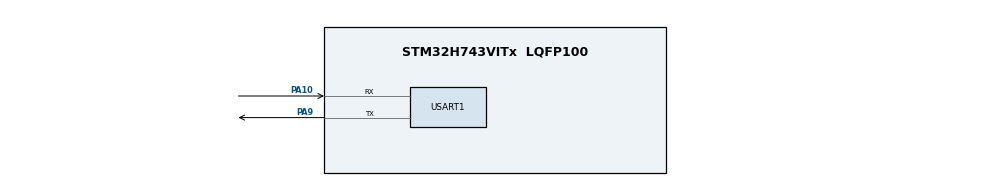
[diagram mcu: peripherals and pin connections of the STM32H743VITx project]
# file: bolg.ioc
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CORTEX_M7.CPU_DCache=Enabled
CORTEX_M7.CPU_ICache=Enabled
Dma.Request0=USART1_RX
Dma.Request1=USART1_TX
Dma.USART1_RX.0.Direction=DMA_PERIPH_TO_MEMORY
Dma.USART1_RX.0.EventEnable=DISABLE
Dma.USART1_RX.0.FIFOMode=DMA_FIFOMODE_DISABLE
Dma.USART1_RX.0.Instance=DMA1_Stream0
Dma.USART1_RX.0.MemDataAlignment=DMA_MDATAALIGN_BYTE
Dma.USART1_RX.0.MemInc=DMA_MINC_ENABLE
Dma.USART1_RX.0.Mode=DMA_NORMAL
Dma.USART1_RX.0.PeriphDataAlignment=DMA_PDATAALIGN_BYTE
Dma.USART1_RX.0.PeriphInc=DMA_PINC_DISABLE
Dma.USART1_RX.0.Polarity=HAL_DMAMUX_REQ_GEN_RISING
Dma.USART1_RX.0.Priority=DMA_PRIORITY_VERY_HIGH
Dma.USART1_RX.0.RequestNumber=1
Dma.USART1_RX.0.SignalID=NONE
Dma.USART1_RX.0.SyncEnable=DISABLE
Dma.USART1_RX.0.SyncPolarity=HAL_DMAMUX_SYNC_NO_EVENT
Dma.USART1_RX.0.SyncRequestNumber=1
Dma.USART1_RX.0.SyncSignalID=NONE
Dma.USART1_TX.1.Direction=DMA_MEMORY_TO_PERIPH
Dma.USART1_TX.1.EventEnable=DISABLE
Dma.USART1_TX.1.FIFOMode=DMA_FIFOMODE_DISABLE
Dma.USART1_TX.1.Instance=DMA1_Stream1
Dma.USART1_TX.1.MemDataAlignment=DMA_MDATAALIGN_BYTE
Dma.USART1_TX.1.MemInc=DMA_MINC_ENABLE
Dma.USART1_TX.1.Mode=DMA_NORMAL
Dma.USART1_TX.1.PeriphDataAlignment=DMA_PDATAALIGN_BYTE
Dma.USART1_TX.1.PeriphInc=DMA_PINC_DISABLE
Dma.USART1_TX.1.Polarity=HAL_DMAMUX_REQ_GEN_RISING
Dma.USART1_TX.1.Priority=DMA_PRIORITY_VERY_HIGH
Dma.USART1_TX.1.RequestNumber=1
Dma.USART1_TX.1.SignalID=NONE
Dma.USART1_TX.1.SyncEnable=DISABLE
Dma.USART1_TX.1.SyncPolarity=HAL_DMAMUX_SYNC_NO_EVENT
Dma.USART1_TX.1.SyncRequestNumber=1
Dma.USART1_TX.1.SyncSignalID=NONE
Mcu.Family=STM32H7
Mcu.Name=STM32H743VITx
Mcu.Package=LQFP100
NVIC.DMA1_Stream0_IRQn=true\:0\:0\:false\:false\:true\:false\:true
NVIC.DMA1_Stream1_IRQn=true\:0\:0\:false\:false\:true\:false\:true
NVIC.PriorityGroup=NVIC_PRIORITYGROUP_4
NVIC.USART1_IRQn=true\:3\:0\:true\:false\:true\:true\:true
PA10.Mode=Asynchronous
PA10.Signal=USART1_RX
PA13\ (JTMS/SWDIO).Mode=Serial_Wire
PA13\ (JTMS/SWDIO).Signal=DEBUG_JTMS-SWDIO
PA14\ (JTCK/SWCLK).Mode=Serial_Wire
PA14\ (JTCK/SWCLK).Signal=DEBUG_JTCK-SWCLK
PA9.Mode=Asynchronous
PA9.Signal=USART1_TX
PC14-OSC32_IN\ (OSC32_IN).Mode=LSE-External-Oscillator
PC14-OSC32_IN\ (OSC32_IN).Signal=RCC_OSC32_IN
PC15-OSC32_OUT\ (OSC32_OUT).Mode=LSE-External-Oscillator
PC15-OSC32_OUT\ (OSC32_OUT).Signal=RCC_OSC32_OUT
PH0-OSC_IN\ (PH0).Mode=HSE-External-Oscillator
PH0-OSC_IN\ (PH0).Signal=RCC_OSC_IN
PH1-OSC_OUT\ (PH1).Mode=HSE-External-Oscillator
PH1-OSC_OUT\ (PH1).Signal=RCC_OSC_OUT
ProjectManager.HeapSize=0x200
ProjectManager.StackSize=0x400
ProjectManager.TargetToolchain=MDK-ARM V5.27
RCC.ADCFreq_Value=50390625
RCC.APB1Freq_Value=120000000
RCC.APB2Freq_Value=120000000
RCC.APB3Freq_Value=120000000
RCC.APB4Freq_Value=120000000
RCC.CortexFreq_Value=480000000
RCC.D1PPRE=RCC_APB3_DIV2
RCC.D2PPRE1=RCC_APB1_DIV2
RCC.D2PPRE2=RCC_APB2_DIV2
RCC.D3PPRE=RCC_APB4_DIV2
RCC.DIVM1=5
RCC.DIVN1=192
RCC.HCLKFreq_Value=240000000
RCC.HPRE=RCC_HCLK_DIV2
RCC.PLL2FRACN=0
RCC.PLL3FRACN=0
RCC.PLLFRACN=0
RCC.PLLSourceVirtual=RCC_PLLSOURCE_HSE
RCC.SYSCLKFreq_VALUE=480000000
RCC.SYSCLKSource=RCC_SYSCLKSOURCE_PLLCLK
RCC.USBFreq_Value=480000000
USART1.VirtualMode-Asynchronous=VM_ASYNC
board=custom

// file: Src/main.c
/* USER CODE BEGIN Header */
/**
  ******************************************************************************
  * @file           : main.c
  * @brief          : Main program body
  ******************************************************************************
  * @attention
  *
  * <h2><center>&copy; Copyright (c) 2020 STMicroelectronics.
  * All rights reserved.</center></h2>
  *
  * This software component is licensed by ST under BSD 3-Clause license,
  * the "License"; You may not use this file except in compliance with the
  * License. You may obtain a copy of the License at:
  *                        opensource.org/licenses/BSD-3-Clause
  *
  ******************************************************************************
  */
/* USER CODE END Header */

#include "main.h"
#include "dma.h"
#include "usart.h"
#include "gpio.h"

/* USER CODE BEGIN Includes */
#include "My_Uart.h"
/* USER CODE END Includes */

void SystemClock_Config(void);

int main(void)
{

  /* Enable I-Cache---------------------------------------------------------*/
  SCB_EnableICache();

  /* Enable D-Cache---------------------------------------------------------*/
  SCB_EnableDCache();

  /* MCU Configuration--------------------------------------------------------*/

  /* Reset of all peripherals, Initializes the Flash interface and the Systick. */
  HAL_Init();

  /* Configure the system clock */
  SystemClock_Config();

  /* Initialize all configured peripherals */
  MX_GPIO_Init();
  MX_DMA_Init();
  MX_USART1_UART_Init();
  /* USER CODE BEGIN 2 */
__HAL_UART_ENABLE_IT(&huart1, UART_IT_IDLE);
  /* USER CODE END 2 */

  /* Infinite loop */
  /* USER CODE BEGIN WHILE */
  while (1)
  {
	if(UsartType.RX_flag)
	{
		UsartType.RX_flag=0;
		HAL_UART_Transmit_DMA(&huart1, (uint8_t *)UsartType.RX_pData, RX_LEN);
	}
    /* USER CODE END WHILE */

  }
}

void SystemClock_Config(void)
{
  RCC_OscInitTypeDef RCC_OscInitStruct = {0};
  RCC_ClkInitTypeDef RCC_ClkInitStruct = {0};
  RCC_PeriphCLKInitTypeDef PeriphClkInitStruct = {0};

  /** Supply configuration update enable
  */
  HAL_PWREx_ConfigSupply(PWR_LDO_SUPPLY);
  /** Configure the main internal regulator output voltage
  */
  __HAL_PWR_VOLTAGESCALING_CONFIG(PWR_REGULATOR_VOLTAGE_SCALE0);

  while(!__HAL_PWR_GET_FLAG(PWR_FLAG_VOSRDY)) {}
  /** Initializes the CPU, AHB and APB busses clocks
  */
  RCC_OscInitStruct.OscillatorType = RCC_OSCILLATORTYPE_HSE;
  RCC_OscInitStruct.HSEState = RCC_HSE_ON;
  RCC_OscInitStruct.PLL.PLLState = RCC_PLL_ON;
  RCC_OscInitStruct.PLL.PLLSource = RCC_PLLSOURCE_HSE;
  RCC_OscInitStruct.PLL.PLLM = 5;
  RCC_OscInitStruct.PLL.PLLN = 192;
  RCC_OscInitStruct.PLL.PLLP = 2;
  RCC_OscInitStruct.PLL.PLLQ = 2;
  RCC_OscInitStruct.PLL.PLLR = 2;
  RCC_OscInitStruct.PLL.PLLRGE = RCC_PLL1VCIRANGE_2;
  RCC_OscInitStruct.PLL.PLLVCOSEL = RCC_PLL1VCOWIDE;
  RCC_OscInitStruct.PLL.PLLFRACN = 0;
  if (HAL_RCC_OscConfig(&RCC_OscInitStruct) != HAL_OK)
  {
    Error_Handler();
  }
  /** Initializes the CPU, AHB and APB busses clocks
  */
  RCC_ClkInitStruct.ClockType = RCC_CLOCKTYPE_HCLK|RCC_CLOCKTYPE_SYSCLK
                              |RCC_CLOCKTYPE_PCLK1|RCC_CLOCKTYPE_PCLK2
                              |RCC_CLOCKTYPE_D3PCLK1|RCC_CLOCKTYPE_D1PCLK1;
  RCC_ClkInitStruct.SYSCLKSource = RCC_SYSCLKSOURCE_PLLCLK;
  RCC_ClkInitStruct.SYSCLKDivider = RCC_SYSCLK_DIV1;
  RCC_ClkInitStruct.AHBCLKDivider = RCC_HCLK_DIV2;
  RCC_ClkInitStruct.APB3CLKDivider = RCC_APB3_DIV2;
  RCC_ClkInitStruct.APB1CLKDivider = RCC_APB1_DIV2;
  RCC_ClkInitStruct.APB2CLKDivider = RCC_APB2_DIV2;
  RCC_ClkInitStruct.APB4CLKDivider = RCC_APB4_DIV2;

  if (HAL_RCC_ClockConfig(&RCC_ClkInitStruct, FLASH_LATENCY_4) != HAL_OK)
  {
    Error_Handler();
  }
  PeriphClkInitStruct.PeriphClockSelection = RCC_PERIPHCLK_USART1;
  PeriphClkInitStruct.Usart16ClockSelection = RCC_USART16CLKSOURCE_D2PCLK2;
  if (HAL_RCCEx_PeriphCLKConfig(&PeriphClkInitStruct) != HAL_OK)
  {
    Error_Handler();
  }
}

void Error_Handler(void)
{
}

/************************ (C) COPYRIGHT STMicroelectronics *****END OF FILE****/
